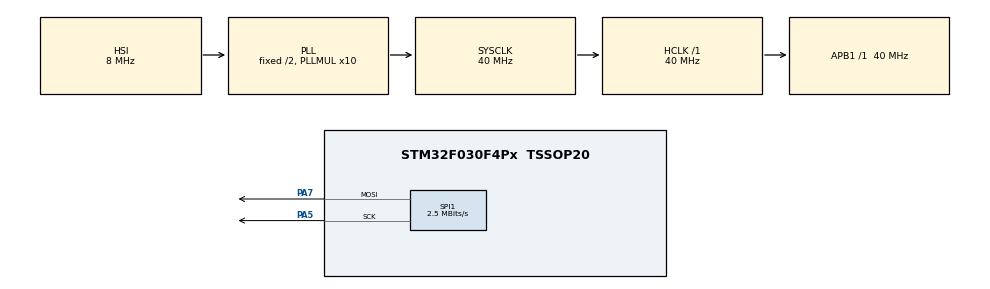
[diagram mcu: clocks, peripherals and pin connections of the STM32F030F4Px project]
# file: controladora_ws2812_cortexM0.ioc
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Mcu.Family=STM32F0
NVIC.TIM14_IRQn=true\:0\:0\:false\:false\:true\:false\:true
Dma.SPI1_TX.0.MemInc=DMA_MINC_ENABLE
Dma.SPI1_TX.0.PeriphInc=DMA_PINC_DISABLE
PA7.Mode=TX_Only_Simplex_Unidirect_Master
SPI1.VirtualType=VM_MASTER
RCC.SYSCLKSource=RCC_SYSCLKSOURCE_PLLCLK
ProjectManager.StackSize=0x400
PA13.Signal=SYS_SWDIO
SPI1.CLKPolarity=SPI_POLARITY_HIGH
ProjectManager.TargetToolchain=STM32CubeIDE
SPI1.Direction=SPI_DIRECTION_2LINES
Dma.SPI1_TX.0.PeriphDataAlignment=DMA_PDATAALIGN_BYTE
RCC.HCLKFreq_Value=40000000
Dma.SPI1_TX.0.Direction=DMA_MEMORY_TO_PERIPH
SPI1.CalculateBaudRate=2.5 MBits/s
PA7.GPIO_PuPd=GPIO_NOPULL
RCC.AHBFreq_Value=40000000
PA5.Signal=SPI1_SCK
board=custom
RCC.PLLMUL=RCC_PLL_MUL10
SPI1.Mode=SPI_MODE_MASTER
PA14.Mode=Serial_Wire
SPI1.DataSize=SPI_DATASIZE_8BIT
Dma.SPI1_TX.0.Instance=DMA1_Channel3
VP_SYS_VS_tim14.Mode=TIM14
PA13.Mode=Serial_Wire
Mcu.Name=STM32F030F4Px
SPI1.NSSPMode=SPI_NSS_PULSE_DISABLE
Dma.SPI1_TX.0.Mode=DMA_NORMAL
RCC.SYSCLKFreq_VALUE=40000000
Mcu.Package=TSSOP20
NVIC.TimeBase=TIM14_IRQn
NVIC.TimeBaseIP=TIM14
PA14.Signal=SYS_SWCLK
ProjectManager.HeapSize=0x200
Dma.SPI1_TX.0.Priority=DMA_PRIORITY_LOW
Dma.SPI1_TX.0.MemDataAlignment=DMA_MDATAALIGN_BYTE
NVIC.DMA1_Channel2_3_IRQn=true\:0\:0\:false\:false\:true\:false\:true
RCC.APB1TimFreq_Value=40000000
Dma.Request0=SPI1_TX
RCC.APB1Freq_Value=40000000
SPI1.BaudRatePrescaler=SPI_BAUDRATEPRESCALER_16
PA5.Mode=TX_Only_Simplex_Unidirect_Master
PA7.Signal=SPI1_MOSI

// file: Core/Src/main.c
/* USER CODE BEGIN Header */
/**
  ******************************************************************************
  * @file           : main.c
  * @brief          : Main program body
  ******************************************************************************
  * @attention
  *
  * <h2><center>&copy; Copyright (c) 2021 STMicroelectronics.
  * All rights reserved.</center></h2>
  *
  * This software component is licensed by ST under BSD 3-Clause license,
  * the "License"; You may not use this file except in compliance with the
  * License. You may obtain a copy of the License at:
  *                        opensource.org/licenses/BSD-3-Clause
  *
  ******************************************************************************
  */
/* USER CODE END Header */
#include "main.h"

/* USER CODE BEGIN Includes */

/* STD includes */
#include <stdint.h>

/* FreeRTOS kernel includes */
#include "FreeRTOS.h"
#include "task.h"

/* User files Includes */
#include "ws2812_task.h"

/* USER CODE END Includes */

SPI_HandleTypeDef hspi1;
DMA_HandleTypeDef hdma_spi1_tx;

/* USER CODE BEGIN PV */

/* FreeRTOS variables on global scope */
TaskHandle_t ws2812_task_handle;

/* USER CODE END PV */

void SystemClock_Config(void);
static void MX_GPIO_Init(void);
static void MX_DMA_Init(void);
static void MX_SPI1_Init(void);

int main(void)
{
  /* USER CODE BEGIN 1 */
  /* FreeRTOS variables on local scope */
  BaseType_t status;

  /* USER CODE END 1 */

  /* MCU Configuration--------------------------------------------------------*/

  /* Reset of all peripherals, Initializes the Flash interface and the Systick. */
  HAL_Init();

  /* Configure the system clock */
  SystemClock_Config();

  /* Initialize all configured peripherals */
  MX_GPIO_Init();
  MX_DMA_Init();
  MX_SPI1_Init();
  /* USER CODE BEGIN 2 */

  /* --------------- FreeRTOS Task management --------------- */
  /* Config. ws2812-task */
  status = xTaskCreate(&ws2812_task, "ws2812-task", 50, NULL, 2, &ws2812_task_handle);
  if(status != pdPASS) while(1);  // Traps the code if the above function returns an unexpected status

  /* Start the freeRTOS scheduler */
  vTaskStartScheduler();

  /* USER CODE END 2 */

  /* Infinite loop */
  while (1)
  {

  }
}

void SystemClock_Config(void)
{
  RCC_OscInitTypeDef RCC_OscInitStruct = {0};
  RCC_ClkInitTypeDef RCC_ClkInitStruct = {0};

  /** Initializes the RCC Oscillators according to the specified parameters
  * in the RCC_OscInitTypeDef structure.
  */
  RCC_OscInitStruct.OscillatorType = RCC_OSCILLATORTYPE_HSI;
  RCC_OscInitStruct.HSIState = RCC_HSI_ON;
  RCC_OscInitStruct.HSICalibrationValue = RCC_HSICALIBRATION_DEFAULT;
  RCC_OscInitStruct.PLL.PLLState = RCC_PLL_ON;
  RCC_OscInitStruct.PLL.PLLSource = RCC_PLLSOURCE_HSI;
  RCC_OscInitStruct.PLL.PLLMUL = RCC_PLL_MUL10;
  RCC_OscInitStruct.PLL.PREDIV = RCC_PREDIV_DIV1;
  if (HAL_RCC_OscConfig(&RCC_OscInitStruct) != HAL_OK)
  {
    Error_Handler();
  }
  /** Initializes the CPU, AHB and APB buses clocks
  */
  RCC_ClkInitStruct.ClockType = RCC_CLOCKTYPE_HCLK|RCC_CLOCKTYPE_SYSCLK
                              |RCC_CLOCKTYPE_PCLK1;
  RCC_ClkInitStruct.SYSCLKSource = RCC_SYSCLKSOURCE_PLLCLK;
  RCC_ClkInitStruct.AHBCLKDivider = RCC_SYSCLK_DIV1;
  RCC_ClkInitStruct.APB1CLKDivider = RCC_HCLK_DIV1;

  if (HAL_RCC_ClockConfig(&RCC_ClkInitStruct, FLASH_LATENCY_1) != HAL_OK)
  {
    Error_Handler();
  }
}

static void MX_SPI1_Init(void)
{

  /* SPI1 parameter configuration*/
  hspi1.Instance = SPI1;
  hspi1.Init.Mode = SPI_MODE_MASTER;
  hspi1.Init.Direction = SPI_DIRECTION_2LINES;
  hspi1.Init.DataSize = SPI_DATASIZE_8BIT;
  hspi1.Init.CLKPolarity = SPI_POLARITY_HIGH;
  hspi1.Init.CLKPhase = SPI_PHASE_1EDGE;
  hspi1.Init.NSS = SPI_NSS_SOFT;
  hspi1.Init.BaudRatePrescaler = SPI_BAUDRATEPRESCALER_16;
  hspi1.Init.FirstBit = SPI_FIRSTBIT_MSB;
  hspi1.Init.TIMode = SPI_TIMODE_DISABLE;
  hspi1.Init.CRCCalculation = SPI_CRCCALCULATION_DISABLE;
  hspi1.Init.CRCPolynomial = 7;
  hspi1.Init.CRCLength = SPI_CRC_LENGTH_DATASIZE;
  hspi1.Init.NSSPMode = SPI_NSS_PULSE_DISABLE;
  if (HAL_SPI_Init(&hspi1) != HAL_OK)
  {
    Error_Handler();
  }

}

static void MX_DMA_Init(void)
{

  /* DMA controller clock enable */
  __HAL_RCC_DMA1_CLK_ENABLE();

  /* DMA interrupt init */
  /* DMA1_Channel2_3_IRQn interrupt configuration */
  HAL_NVIC_SetPriority(DMA1_Channel2_3_IRQn, 0, 0);
  HAL_NVIC_EnableIRQ(DMA1_Channel2_3_IRQn);

}

static void MX_GPIO_Init(void)
{

  /* GPIO Ports Clock Enable */
  __HAL_RCC_GPIOA_CLK_ENABLE();

}

/* USER CODE BEGIN 4 */

void HAL_SPI_TxCpltCallback(SPI_HandleTypeDef *hspi){
	BaseType_t xHigherPriorityTaskWoken;
	xHigherPriorityTaskWoken = pdFALSE;

	/* Notify ws2812_task that the SPI DMA data transfer has completed */
	xTaskNotifyFromISR(ws2812_task_handle, 0, eNoAction, &xHigherPriorityTaskWoken);

	/* Launch the scheduler */
	portYIELD_FROM_ISR(xHigherPriorityTaskWoken);
}

/* USER CODE END 4 */

 /**
  * @brief  Period elapsed callback in non blocking mode
  * @note   This function is called  when TIM14 interrupt took place, inside
  * HAL_TIM_IRQHandler(). It makes a direct call to HAL_IncTick() to increment
  * a global variable "uwTick" used as application time base.
  * @param  htim : TIM handle
  * @retval None
  */
void HAL_TIM_PeriodElapsedCallback(TIM_HandleTypeDef *htim)
{
  if (htim->Instance == TIM14) {
    HAL_IncTick();
  }
}

void Error_Handler(void)
{
  __disable_irq();
  while (1)
  {
  }
}

/************************ (C) COPYRIGHT STMicroelectronics *****END OF FILE****/
